# NM1500_v1 register map
File version: 1.0
Registers are 32-bit, read-write, reset 0x0 unless marked. A register's access mark holds for its fields unless they carry their own. Offsets are from the block's base; [hi:lo] are bit positions; {n}, {i} and the like mark numbered series.

## QEI0 — QEI Register Map
Base 0x401C0000
Same registers: QEI1 0x401C4000
0x00 QEI_CNT — QEI Pulse Counter
  [31:0] QEI_CNT — Quadrature Encoder Pulse Counter. A 24-bit up/down counter. When an effective phase pulse is detected, this counter is increased by one if the bit DIR in EQICTR is one or decreased by one if the bit DIR is 0. This register performs an integrator which count value is proportional to the encoder position. The pulse counter may be initialized to a predetermined value by one of three events occurs:
0x04 QEI_CNTHLD — QEI Pulse Counter Hold Register
  [31:0] QEI_CNTHLD — Quadrature Encoder Pulse Counter Hold Register. When bit HOLDCNT (QEIxCTR[24]) goes from low to high, the QEPCNT value is copied into QEPCNTHLD register.
0x08 QEI_CNTILAT — QEI Pulse Counter Index Latch Register
  [23:0] QEI_CNTILAT — Quadrature Encoder Pulse Counter Index Latch Register. When bit IDXF (QEI_STS[18]) is set, the QEPI_CNT value is copied into QEI_CNTILAT register.
0x0C QEI_CNTCMP — QEI Pulse Counter Compare Register
  [31:0] QEI_CNTCMP — Quadrature Encoder Pulse Counter Compare Register
0x14 QEI_MAXCNT — QEI Pre-set Maximum Count Register
  [31:0] QEI_MAXCNT — Quadrature Encoder Preset Maximum Count Register. This register value determined by user stores the maximum value which may be the number of the quadrature encoder pulses in a revolution for the QEI controller compare-counting mode.
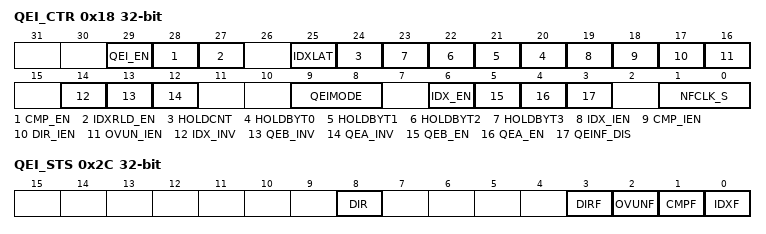
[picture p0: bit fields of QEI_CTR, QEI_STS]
0x18 QEI_CTR — QEI Control Register
  [29] QEI_EN — Quadrature Encoder Interface Controller Enable Bit
    0=QEI controller function Disabled; 1=QEI controller function Enabled
  [28] CMP_EN — The Compare Function Enable Bit. The compare function in QEI controller is to compare the dynamic counting QEPCNT with the compare register QEI_CNTCMP, if QEI_CNT value reaches QEI_CNTCMP, the flag CMPF will be set.
    0=The compare function Disabled; 1=The compare function Enabled
  [27] IDXRLD_EN — Index Trigger QEI_CNT Reload Enable Bit
    0=The reload function Disabled; 1=The QEI_CNT re-initialized by Index signal Enabled
  [25] IDXLAT — Index Latch QEI_CNT Enable Bit. If this bit is set to high, the QEI_CNT content will be latched into QEI_CNTILAT at every rising on signal CHX.
    0=The index signal latch QEI counter function Disabled; 1=The index signal latch QEI counter function Enabled
  [24] HOLDCNT — Hold QEI_CNT Control Bit. When this bit is set from low to high, the QEI_CNT value is copied into QEI_CNTHLD. This bit may be set by writing 1 to itself through software or Timer0~Timer3 interrupt flag (TISTR.TIF). Note: This bit is automatically cleared after QEI_CNTHLD holds QEI_CNT value.
    0=No operation; 1=QEI_CNT content captured and stored in QEI_CNTHLD
  [n+20] HOLDBYT{n} (n=0..3) — Hold QEI_CNT by Timer {n}
    0=TISR{n}.TIF has no effect on HOLDCNT; 1=A rising edge of bit TISR{n}.TIF in timer {n} sets HOLDCNT to 1
  [19] IDX_IEN — Enable IDXF Trigger QEI Interrupt
    0=The IDXF can trigger QEI interrupt Disabled; 1=The IDXF can trigger QEI interrupt Enabled
  [18] CMP_IEN — Enable CMPF Trigger QEI Interrupt
    0=The CMPF can trigger QEI controller interrupt Disabled; 1=The CMPF can trigger QEI controller interrupt Enabled
  [17] DIR_IEN — Enable DIRF Trigger QEI Interrupt
    0=The DIRF can trigger QEI controller interrupt Disabled; 1=The DIRF can trigger QEI controller interrupt Enabled
  [16] OVUN_IEN — Enable OVUNF Trigger QEI Interrupt
    0=The OVUNF can trigger QEI controller interrupt Disabled; 1=The OVUNF can trigger QEI controller interrupt Enabled
  [14] IDX_INV — Inverse IDX Input Polarity
    0=Not inverse IDX input polarity; 1=IDX input polarity is inversed to QEI controller
  [13] QEB_INV — Inverse QEB Input Polarity
    0=Not inverse QEB input polarity; 1=QEB input polarity is inversed to QEI controller
  [12] QEA_INV — Inverse QEA Input Polarity
    0=Not inverse QEA input polarity; 1=QEA input polarity is inversed to QEI controller
  [9:8] QEIMODE — QEI Counting Mode Selection
  [6] IDX_EN — Enable IDX Input to QEI Controller
    0=The IDX input to QEI Controller Disabled; 1=The IDX input to QEI Controller Enabled
  [5] QEB_EN — Enable QEB Input to QEI Controller
    0=The QEB input to QEI Controller Disabled; 1=The QEB input to QEI Controller Enabled
  [4] QEA_EN — Enable QEA Input to QEI Controller
    0=The QEA input to QEI Controller Disabled; 1=The QEA input to QEI Controller Enabled
  [3] QEINF_DIS — Disable QEI Controller Input Noise Filter
    0=The noise filter of QEI controller Enabled; 1=The noise filter of QEI controller Disabled
  [1:0] NFCLK_S — Noise Filter Clock Pre-divided Selection
0x2C QEI_STS — QEI Status Register
  [8] DIR — QEI Counter Counting Direction Indication Bit. Note: This bit is set/reset by hardware according to the phase detection between CHA and CHB.
    0=QEI Counter is in down-counting; 1=QEI Counter is in up-counting
  [3] DIRF — Direction Change Flag. Flag is set by hardware while QEI counter counting direction is changed, software can clear this bit by writing a one to it. Note: This bit is only cleared by writing 1 to itself through software.
    0=No change in QEI counter counting direction; 1=QEI counter counting direction is changed
  [2] OVUNF — QEI Counter Overflow or Underflow Flag. Flag is set by hardware while QEI_CNT overflows from 0xFFFF_FFFF to 0 in Free-counting mode or from the QEI_MAXCNT value to 0 in compare-counting mode. Similarly, the flag is set wile QEI counter underflows from 0 to 0xFFFF_FFFF or QEI_MAXCNT. Note: This bit is only cleared by writing 1 to itself through software.
    0=No overflow or underflow occurred in QEI counter; 1=QEI counter occurred counting overflow or underflow
  [1] CMPF — Compare-match Flag. If the QEI compare function is enabled, the flag is set by hardware while QEI counter up or down counts and reach to the QEI_CNTCMP value. Note: This bit is only cleared by writing 1 to itself through software.
    0=QEI counter does not match with QEI_CNTCMP value; 1=QEI counter counts to the same as QEI_CNTCMP value
  [0] IDXF — IDX Detected Flag. When the QEI controller detects a rising edge on signal CHX it will set flag IDXF to high. Note: This bit is only cleared by writing 1 to itself through software.
    0=No rising edge detected on signal CHX; 1=A rising edge occurred on signal CHX
